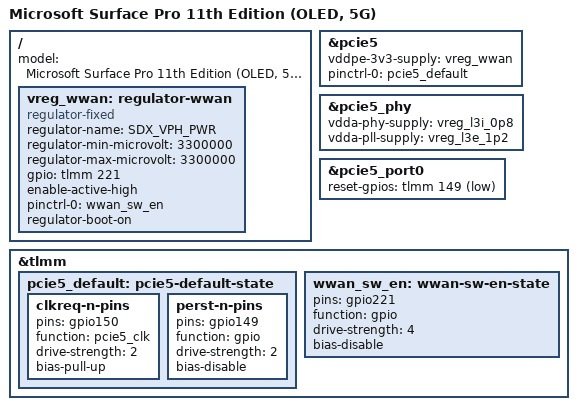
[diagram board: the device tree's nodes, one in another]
// SPDX-License-Identifier: BSD-3-Clause

/dts-v1/;

#include "x1e80100-microsoft-denali-oled.dts"

/ {
	model = "Microsoft Surface Pro 11th Edition (OLED, 5G)";

	/* The modem's supply switch, as on the CRD */
	vreg_wwan: regulator-wwan {
		compatible = "regulator-fixed";

		regulator-name = "SDX_VPH_PWR";
		regulator-min-microvolt = <3300000>;
		regulator-max-microvolt = <3300000>;

		gpio = <&tlmm 221 GPIO_ACTIVE_HIGH>;
		enable-active-high;

		pinctrl-0 = <&wwan_sw_en>;
		pinctrl-names = "default";

		regulator-boot-on;
	};
};

/* The Snapdragon X65 modem, wired as on the CRD */
&pcie5 {
	vddpe-3v3-supply = <&vreg_wwan>;

	pinctrl-0 = <&pcie5_default>;
	pinctrl-names = "default";

	status = "okay";
};

&pcie5_phy {
	vdda-phy-supply = <&vreg_l3i_0p8>;
	vdda-pll-supply = <&vreg_l3e_1p2>;

	status = "okay";
};

&pcie5_port0 {
	reset-gpios = <&tlmm 149 GPIO_ACTIVE_LOW>;
};

&tlmm {
	pcie5_default: pcie5-default-state {
		clkreq-n-pins {
			pins = "gpio150";
			function = "pcie5_clk";
			drive-strength = <2>;
			bias-pull-up;
		};

		perst-n-pins {
			pins = "gpio149";
			function = "gpio";
			drive-strength = <2>;
			bias-disable;
		};
	};

	wwan_sw_en: wwan-sw-en-state {
		pins = "gpio221";
		function = "gpio";
		drive-strength = <4>;
		bias-disable;
	};
};
